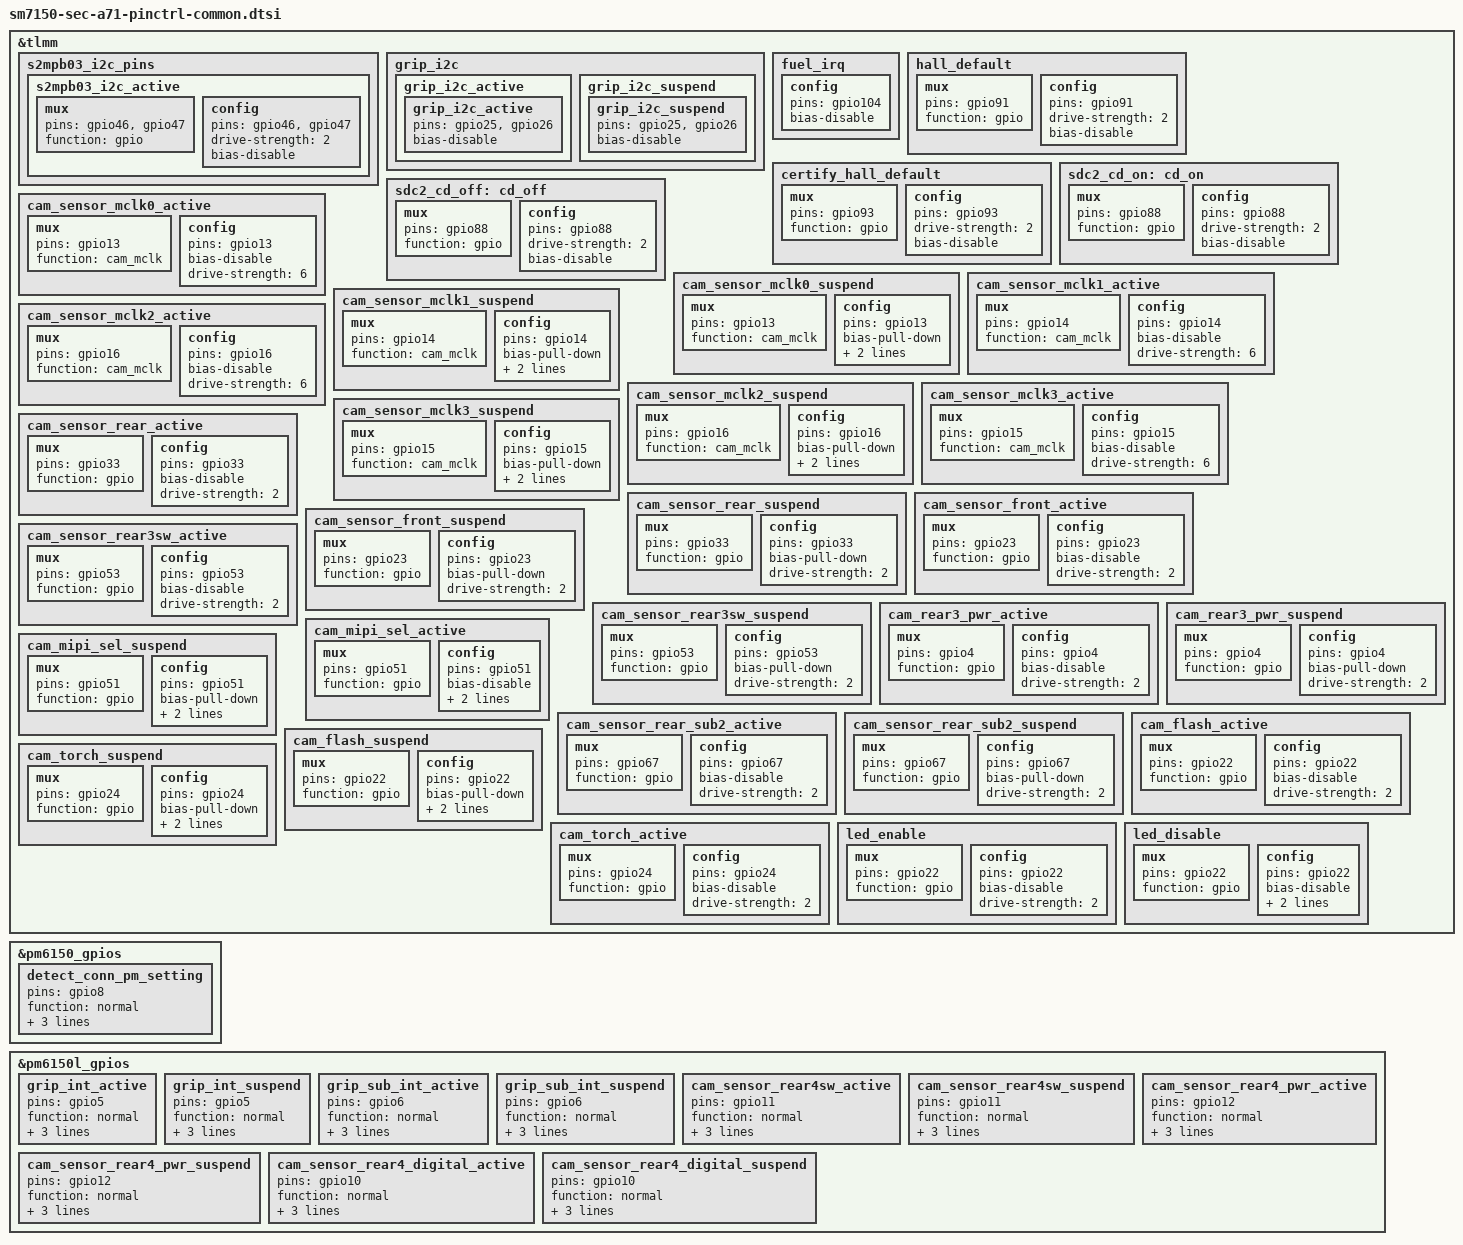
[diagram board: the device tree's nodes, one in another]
/* Copyright (c) 2019, The Linux Foundation. All rights reserved.
 *
 * This program is free software; you can redistribute it and/or modify
 * it under the terms of the GNU General Public License version 2 and
 * only version 2 as published by the Free Software Foundation.
 *
 * This program is distributed in the hope that it will be useful,
 * but WITHOUT ANY WARRANTY; without even the implied warranty of
 * MERCHANTABILITY or FITNESS FOR A PARTICULAR PURPOSE.  See the
 * GNU General Public License for more details.
 */

#include "../drivers/sm7150-sec-a71-audio-pinctrl.dtsi"

&tlmm {
	s2mpb03_i2c_pins {
		s2mpb03_i2c_active: s2mpb03_i2c_active {
			mux {
				pins = "gpio46", "gpio47";
				function = "gpio";
			};
			config {
				pins = "gpio46", "gpio47";
				drive-strength = <2>;
				bias-disable;
			};
		};
	};
    
	grip_i2c {
		grip_i2c_active: grip_i2c_active {
			grip_i2c_active {
				pins = "gpio25", "gpio26";
				bias-disable;
			};
		};
		grip_i2c_suspend: grip_i2c_suspend {
			grip_i2c_suspend {
				pins = "gpio25", "gpio26";
				bias-disable;
			};
		};
	};
	
	fuel_irq: fuel_irq {
		config {
			pins = "gpio104";
			bias-disable;         /* No PULL */
		};
	};

	hall_default: hall_default {
		mux {
			pins = "gpio91";
			function = "gpio";
		};
		config {
			pins = "gpio91";
			drive-strength = <2>;
			bias-disable;
		};
	};

	certify_hall_default: certify_hall_default {
		mux {
			pins = "gpio93";
			function = "gpio";
		};
		config {
			pins = "gpio93";
			drive-strength = <2>;
			bias-disable;
		};
	};

	sdc2_cd_on: cd_on {
			mux {
				pins = "gpio88";
				function = "gpio";
			};

			config {
				pins = "gpio88";
				drive-strength = <2>;
				bias-disable;
			};
	};
	
	sdc2_cd_off: cd_off {
			mux {
				pins = "gpio88";
				function = "gpio";
			};

			config {
				pins = "gpio88";
				drive-strength = <2>;
				bias-disable;
			};
	};

	cam_sensor_mclk0_active: cam_sensor_mclk0_active {
      	/* Main Rear MCLK */
		mux {
			pins = "gpio13";
			function = "cam_mclk";
		};
		config {
			pins = "gpio13";
			bias-disable; /* No PULL */
			drive-strength = <6>; /* 6 MA */
		};
	};

	cam_sensor_mclk0_suspend: cam_sensor_mclk0_suspend {
	/* Main Rear MCLK */
		mux {
			pins = "gpio13";
			function = "cam_mclk";
		};
		config {
			pins = "gpio13";
			bias-pull-down; /* No PULL */
			drive-strength = <6>; /* 6 MA */
                        output-low;
		};
	};

	cam_sensor_mclk1_active: cam_sensor_mclk1_active {
      	/* FRONT MCLK */
		mux {
			pins = "gpio14";
			function = "cam_mclk";
		};
		config {
			pins = "gpio14";
			bias-disable; /* No PULL */
			drive-strength = <6>; /* 6 MA */
		};
	};

	cam_sensor_mclk1_suspend: cam_sensor_mclk1_suspend {
	/* FRONT MCLK */
		mux {
			pins = "gpio14";
			function = "cam_mclk";
		};
		config {
			pins = "gpio14";
			bias-pull-down; /* No PULL */
			drive-strength = <6>; /* 6 MA */
                        output-low;
		};
	};

	cam_sensor_mclk2_active: cam_sensor_mclk2_active {
      	/* Bokeh Cam MCLK */
		mux {
			pins = "gpio16";
			function = "cam_mclk";
		};
		config {
			pins = "gpio16";
			bias-disable; /* No PULL */
			drive-strength = <6>; /* 6 MA */
		};
	};

	cam_sensor_mclk2_suspend: cam_sensor_mclk2_suspend {
	/* Bokeh Cam MCLK */
		mux {
			pins = "gpio16";
			function = "cam_mclk";
		};
		config {
			pins = "gpio16";
			bias-pull-down; /* No PULL */
			drive-strength = <6>; /* 6 MA */
			output-low;
		};
	};

	cam_sensor_mclk3_active: cam_sensor_mclk3_active {
      	/* UW Cam MCLK */
		mux {
			pins = "gpio15";
			function = "cam_mclk";
		};
		config {
			pins = "gpio15";
			bias-disable; /* No PULL */
			drive-strength = <6>; /* 6 MA */
		};
	};

	cam_sensor_mclk3_suspend: cam_sensor_mclk3_suspend {
	/* UW Cam MCLK */
		mux {
			pins = "gpio15";
			function = "cam_mclk";
		};
		config {
			pins = "gpio15";
			bias-pull-down; /* No PULL */
			drive-strength = <6>; /* 6 MA */
                        output-low;

		};
	};
		
	cam_sensor_rear_active: cam_sensor_rear_active {
	/* Main Rear reset */
		mux {
			pins = "gpio33";
			function = "gpio";
		};
		config {
			pins = "gpio33";
			bias-disable; /* No PULL */
			drive-strength = <2>; /* 2 MA */
		};
	};
	cam_sensor_rear_suspend: cam_sensor_rear_suspend {
	/* Main Rear reset */
		mux {
			pins = "gpio33";
			function = "gpio";
		};
		config {
			pins = "gpio33";
			bias-pull-down; /* PULL DOWN */
			drive-strength = <2>; /* 2 MA */
		};
	};

	cam_sensor_front_active: cam_sensor_front_active {
	/* FRONT RESET */
		mux {
			pins = "gpio23";
			function = "gpio";
		};
		config {
			pins = "gpio23";
			bias-disable; /* No PULL */
			drive-strength = <2>; /* 2 MA */
		};
	};
	cam_sensor_front_suspend: cam_sensor_front_suspend {
	/* FRONT RESET */
		mux {
			pins = "gpio23";
			function = "gpio";
		};
		config {
			pins = "gpio23";
			bias-pull-down; /* PULL DOWN */
			drive-strength = <2>; /* 2 MA */
		};
	};



	cam_sensor_rear3sw_active: cam_sensor_rear3sw_active {
	/* UW Cam RESET */
		mux {
			pins = "gpio53";
			function = "gpio";
		};
		config {
			pins = "gpio53";
			bias-disable; /* No PULL */
			drive-strength = <2>; /* 2 MA */
		};
	};
	cam_sensor_rear3sw_suspend: cam_sensor_rear3sw_suspend {
	/* UW Cam RESET */
		mux {
			pins = "gpio53";
			function = "gpio";
		};
		config {
			pins = "gpio53";
			bias-pull-down; /* PULL DOWN */
			drive-strength = <2>; /* 2 MA */
		};
	};
	
	cam_rear3_pwr_active: cam_rear3_pwr_active {
	/* UW VANA */
		mux {
			pins = "gpio4";
			function = "gpio";
		};
		config {
			pins = "gpio4";
			bias-disable; /* No PULL */
			drive-strength = <2>; /* 2 MA */
		};
	};
	cam_rear3_pwr_suspend: cam_rear3_pwr_suspend {
	/* UW VANA */
		mux {
			pins = "gpio4";
			function = "gpio";
		};
		config {
			pins = "gpio4";
			bias-pull-down; /* PULL DOWN */
			drive-strength = <2>; /* 2 MA */
		};
	};

	cam_mipi_sel_active: cam_mipi_sel_active {
	/* MIPI SEL */
		mux {
			pins = "gpio51";
			function = "gpio";
		};
		config {
			pins = "gpio51";
			bias-disable; 
			output-high;
			drive-strength = <2>; /* 2 MA */
		};
	};
	cam_mipi_sel_suspend: cam_mipi_sel_suspend {
	/* MIPI SEL */
		mux {
			pins = "gpio51";
			function = "gpio";
		};
		config {
			pins = "gpio51";
			bias-pull-down;
                        output-low;
			drive-strength = <2>; /* 2 MA */
		};
	};

	cam_sensor_rear_sub2_active: cam_sensor_rear_sub2_active {
	/* Bokeh Cam RESET */
		mux {
			pins = "gpio67";
			function = "gpio";
		};
		config {
			pins = "gpio67";
			bias-disable; /* No PULL */
			drive-strength = <2>; /* 2 MA */
		};
	};
	
	cam_sensor_rear_sub2_suspend: cam_sensor_rear_sub2_suspend {
	/* Bokeh Cam RESET */
		mux {
			pins = "gpio67";
			function = "gpio";
		};
		config {
			pins = "gpio67";
			bias-pull-down; /* PULL DOWN */
			drive-strength = <2>; /* 2 MA */
		};
	};

	cam_flash_active: cam_flash_active {
	/* TORCH, FLASH */
		mux {
			pins = "gpio22";
			function = "gpio";
		};
		config {
			pins = "gpio22";
			bias-disable; /* No PULL */
			drive-strength = <2>; /* 2 MA */
		};
	};

	cam_flash_suspend: cam_flash_suspend {
	/* TORCH, FLASH */
		mux {
			pins = "gpio22";
			function = "gpio";
		};
		config {
			pins = "gpio22";
			bias-pull-down; /* PULL DOWN */
			drive-strength = <2>; /* 2 MA */
                        output-low;
		};
	};

	cam_torch_active: cam_torch_active {
	/* TORCH, FLASH */
		mux {
			pins = "gpio24";
			function = "gpio";
		};
		config {
			pins = "gpio24";
			bias-disable; /* No PULL */
			drive-strength = <2>; /* 2 MA */
		};
	};

	cam_torch_suspend: cam_torch_suspend {
	/* TORCH, FLASH */
		mux {
			pins = "gpio24";
			function = "gpio";
		};
		config {
			pins = "gpio24";
			bias-pull-down; /* PULL DOWN */
			drive-strength = <2>; /* 2 MA */
                        output-low;
		};
	};

	led_enable: led_enable {
		mux {
			pins = "gpio22";
			function = "gpio";
		};

		config {
			pins = "gpio22";
			bias-disable; /* No PULL */
			drive-strength = <2>; /* 2 MA */
		};
	};

	led_disable: led_disable {
		mux {
			pins = "gpio22";
			function = "gpio";
		};

		config {
			pins = "gpio22";
			bias-disable; /* No PULL */
			drive-strength = <2>; /* 2 MA */
			output-low;
		};
	};

};

&pm6150_gpios {
	detect_conn_pm_setting: detect_conn_pm_setting {
		pins = "gpio8"; /* SUB_DET */
		function = "normal";
		power-source = <0>;
		bias-disable; /* NO PULL */
		input-enable;
	};

};

&pm6150l_gpios {
	grip_int_active: grip_int_active {
		pins = "gpio5";
		function = "normal";
		power-source = <0>;
		input-enable;
		bias-disable;
	};
	grip_int_suspend: grip_int_suspend {
		pins = "gpio5";
		function = "normal";
		power-source = <0>;
		input-enable;
		bias-disable;
	};

	grip_sub_int_active: grip_sub_int_active {
		pins = "gpio6";
		function = "normal";
		power-source = <0>;
		input-enable;
		bias-disable;
	};
	grip_sub_int_suspend: grip_sub_int_suspend {
		pins = "gpio6";
		function = "normal";
		power-source = <0>;
		input-enable;
		bias-disable;
	};

	cam_sensor_rear4sw_active: cam_sensor_rear4sw_active{
		pins = "gpio11";
		function = "normal";
		power-source = <1>;
		input-enable;
		bias-disable;
	};

	cam_sensor_rear4sw_suspend: cam_sensor_rear4sw_suspend{
		pins = "gpio11";
		function = "normal";
		power-souce = <1>;
		input-enable;
		bias-disable;
	};


	cam_sensor_rear4_pwr_active: cam_sensor_rear4_pwr_active{
		pins = "gpio12";
		function = "normal";
		power-source = <0>;
		input-enable;
		bias-disable;
	};

	cam_sensor_rear4_pwr_suspend: cam_sensor_rear4_pwr_suspend{
		pins = "gpio12";
		function = "normal";
		power-source = <0>;
		input-enable;
		bias-disable;
	};

	
	cam_sensor_rear4_digital_active: cam_sensor_rear4_digital_active{
		pins = "gpio10";
		function = "normal";
		power-source = <0>;
		input-enable;
		bias-disable;
	};

	cam_sensor_rear4_digital_suspend: cam_sensor_rear4_digital_suspend{
		pins = "gpio10";
		function = "normal";
		power-source = <0>;
		input-enable;
		bias-disable;
	};

};
